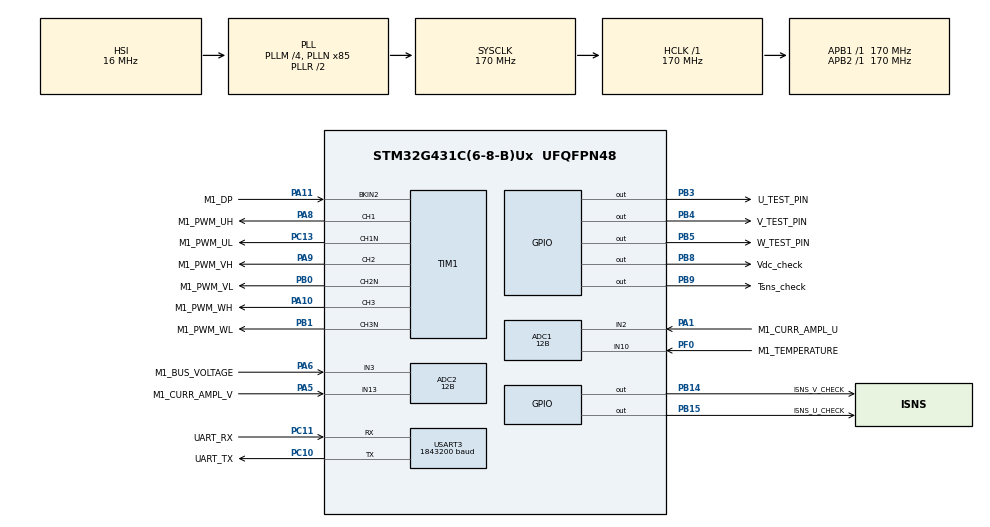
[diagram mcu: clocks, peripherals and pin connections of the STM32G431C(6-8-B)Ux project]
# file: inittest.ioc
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ADC1.Channel-1\#ChannelRegularConversion=ADC_CHANNEL_10
ADC1.ClockPrescaler=ADC_CLOCK_ASYNC_DIV1
ADC1.ContinuousConvMode=DISABLE
ADC1.DMAContinuousRequests=DISABLE
ADC1.DataAlign=ADC_DATAALIGN_LEFT
ADC1.DiscontinuousConvMode=DISABLE
ADC1.EOCSelection=ADC_EOC_SINGLE_CONV
ADC1.EnableAnalogWatchDog1=false
ADC1.EnableAnalogWatchDog2=false
ADC1.EnableAnalogWatchDog3=false
ADC1.EnableInjectedConversion=ENABLE
ADC1.EnableRegularConversion=ENABLE
ADC1.ExternalTrigConv=ADC_SOFTWARE_START
ADC1.ExternalTrigConvEdge=ADC_EXTERNALTRIGCONVEDGE_NONE
ADC1.ExternalTrigInjecConv=ADC_EXTERNALTRIGINJEC_T1_TRGO
ADC1.ExternalTrigInjecConvEdge=ADC_EXTERNALTRIGINJECCONV_EDGE_RISING
ADC1.InjNumberOfConversion=1
ADC1.InjectedChannel-1\#ChannelInjectedConversion=ADC_CHANNEL_2
ADC1.InjectedConvMode=None
ADC1.InjectedOffset-1\#ChannelInjectedConversion=0
ADC1.InjectedOffsetNumber-1\#ChannelInjectedConversion=ADC_OFFSET_NONE
ADC1.InjectedRank-1\#ChannelInjectedConversion=1
ADC1.InjectedSamplingTime-1\#ChannelInjectedConversion=ADC_SAMPLETIME_6CYCLES_5
ADC1.LowPowerAutoWait=DISABLE
ADC1.NbrOfConversion=1
ADC1.NbrOfConversionFlag=1
ADC1.Offset-1\#ChannelRegularConversion=0
ADC1.OffsetNumber-1\#ChannelRegularConversion=ADC_OFFSET_NONE
ADC1.Overrun=ADC_OVR_DATA_PRESERVED
ADC1.Rank-1\#ChannelRegularConversion=1
ADC1.Resolution=ADC_RESOLUTION_12B
ADC1.SamplingTime-1\#ChannelRegularConversion=ADC_SAMPLETIME_47CYCLES_5
ADC1.ScanConvMode=ADC_SCAN_DISABLE
ADC1.master=1
ADC2.Channel-1\#ChannelRegularConversion=ADC_CHANNEL_3
ADC2.ClockPrescaler=ADC_CLOCK_ASYNC_DIV1
ADC2.ContinuousConvMode=DISABLE
ADC2.DMAContinuousRequests=DISABLE
ADC2.DataAlign=ADC_DATAALIGN_LEFT
ADC2.DiscontinuousConvMode=DISABLE
ADC2.EOCSelection=ADC_EOC_SINGLE_CONV
ADC2.EnableAnalogWatchDog1=false
ADC2.EnableAnalogWatchDog2=false
ADC2.EnableAnalogWatchDog3=false
ADC2.EnableInjectedConversion=ENABLE
ADC2.EnableRegularConversion=ENABLE
ADC2.ExternalTrigConv=ADC_SOFTWARE_START
ADC2.ExternalTrigConvEdge=ADC_EXTERNALTRIGCONVEDGE_NONE
ADC2.ExternalTrigInjecConv=ADC_EXTERNALTRIGINJEC_T1_TRGO
ADC2.ExternalTrigInjecConvEdge=ADC_EXTERNALTRIGINJECCONV_EDGE_RISING
ADC2.InjNumberOfConversion=1
ADC2.InjectedChannel-1\#ChannelInjectedConversion=ADC_CHANNEL_13
ADC2.InjectedConvMode=None
ADC2.InjectedOffset-1\#ChannelInjectedConversion=0
ADC2.InjectedOffsetNumber-1\#ChannelInjectedConversion=ADC_OFFSET_NONE
ADC2.InjectedRank-1\#ChannelInjectedConversion=1
ADC2.InjectedSamplingTime-1\#ChannelInjectedConversion=ADC_SAMPLETIME_6CYCLES_5
ADC2.LowPowerAutoWait=DISABLE
ADC2.NbrOfConversion=1
ADC2.NbrOfConversionFlag=1
ADC2.Offset-1\#ChannelRegularConversion=0
ADC2.OffsetNumber-1\#ChannelRegularConversion=ADC_OFFSET_NONE
ADC2.Overrun=ADC_OVR_DATA_PRESERVED
ADC2.Rank-1\#ChannelRegularConversion=1
ADC2.Resolution=ADC_RESOLUTION_12B
ADC2.SamplingTime-1\#ChannelRegularConversion=ADC_SAMPLETIME_47CYCLES_5
ADC2.ScanConvMode=ADC_SCAN_DISABLE
ADC2.master=1
Dma.Request0=USART3_RX
Dma.Request1=USART3_TX
Dma.USART3_RX.0.Direction=DMA_PERIPH_TO_MEMORY
Dma.USART3_RX.0.EventEnable=DISABLE
Dma.USART3_RX.0.Instance=DMA1_Channel1
Dma.USART3_RX.0.MemDataAlignment=DMA_MDATAALIGN_BYTE
Dma.USART3_RX.0.MemInc=DMA_MINC_ENABLE
Dma.USART3_RX.0.Mode=DMA_NORMAL
Dma.USART3_RX.0.PeriphDataAlignment=DMA_PDATAALIGN_BYTE
Dma.USART3_RX.0.PeriphInc=DMA_PINC_DISABLE
Dma.USART3_RX.0.Polarity=HAL_DMAMUX_REQ_GEN_RISING
Dma.USART3_RX.0.Priority=DMA_PRIORITY_LOW
Dma.USART3_RX.0.RequestNumber=1
Dma.USART3_RX.0.SignalID=NONE
Dma.USART3_RX.0.SyncEnable=DISABLE
Dma.USART3_RX.0.SyncPolarity=HAL_DMAMUX_SYNC_NO_EVENT
Dma.USART3_RX.0.SyncRequestNumber=1
Dma.USART3_RX.0.SyncSignalID=NONE
Dma.USART3_TX.1.Direction=DMA_MEMORY_TO_PERIPH
Dma.USART3_TX.1.EventEnable=DISABLE
Dma.USART3_TX.1.Instance=DMA1_Channel2
Dma.USART3_TX.1.MemDataAlignment=DMA_MDATAALIGN_BYTE
Dma.USART3_TX.1.MemInc=DMA_MINC_ENABLE
Dma.USART3_TX.1.Mode=DMA_NORMAL
Dma.USART3_TX.1.PeriphDataAlignment=DMA_PDATAALIGN_BYTE
Dma.USART3_TX.1.PeriphInc=DMA_PINC_DISABLE
Dma.USART3_TX.1.Polarity=HAL_DMAMUX_REQ_GEN_RISING
Dma.USART3_TX.1.Priority=DMA_PRIORITY_LOW
Dma.USART3_TX.1.RequestNumber=1
Dma.USART3_TX.1.SignalID=NONE
Dma.USART3_TX.1.SyncEnable=DISABLE
Dma.USART3_TX.1.SyncPolarity=HAL_DMAMUX_SYNC_NO_EVENT
Dma.USART3_TX.1.SyncRequestNumber=1
Dma.USART3_TX.1.SyncSignalID=NONE
ExtraMW=MotorControl
ExtraMW.MotorControl.Config=MotorControl
ExtraMW.MotorControl.Mode=MotorControl
ExtraMW.MotorControl.Root=MCSDK_v6.4.1-Full/MotorControl
ExtraMW.MotorControl.Template=templates
Mcu.Family=STM32G4
Mcu.Name=STM32G431C(6-8-B)Ux
Mcu.Package=UFQFPN48
MotorControl.ADC_1_PERIPH=ADC1
MotorControl.ADC_2_PERIPH=ADC2
MotorControl.ADC_AHBPERIPH=RCC_AHBPeriph_ADC12
MotorControl.ADC_CLOCK_WB_DIV=1
MotorControl.ADC_PERIPH=ADC1
MotorControl.ADC_REFERENCE_VOLTAGE=3.3
MotorControl.BOARD=UAV
MotorControl.BUS_VOLTAGE_READING=true
MotorControl.CCMRAM_ENABLED=false
MotorControl.CLOCK_FREQUENCY=CPU_CLK_170_MHZ
MotorControl.CLOCK_SOURCE=INTERNAL
MotorControl.CPU_CLK_170_MHZ=true
MotorControl.CTLBOARD_NAME=UAV
MotorControl.CUBE_MX_VER=6.16.1
MotorControl.CURRENT_READING_TOPOLOGY=ICS_SENSORS
MotorControl.CURR_SAMPLING_TIME=6
MotorControl.DBG_MCU_LOAD_MEASURE=false
MotorControl.DEBUG_DAC_FUNCTIONALITY_EN=false
MotorControl.DP_EMERGENCY_STOP_GPIO_PIN=LL_GPIO_PIN_11
MotorControl.DP_EMERGENCY_STOP_GPIO_PORT=GPIOA
MotorControl.DRIVES_NUMBER_SELECTION=SINGLEDRIVE
MotorControl.DRIVE_NUMBER=1
MotorControl.DRIVE_TYPE=FOC
MotorControl.ENCODER_AVAILABLE=false
MotorControl.ENCODER_PPR=400
MotorControl.EXT_CLOCK_FREQUENCY=INT_RC_OSC
MotorControl.FEEDBACK_NET_FILTERING=false
MotorControl.FLASH_SIZE=128
MotorControl.HALL_SENSORS_AVAILABLE=false
MotorControl.HIGH_SIDE_IDLE_STATE=false
MotorControl.HWV_CS=TwoICSCurrents
MotorControl.HWV_DP=SingleErrorTrigger_FixedReference
MotorControl.HWV_PWM=DrivingHighAndLowSides
MotorControl.HW_COMPLEMENTED_LOW_SIDE=false
MotorControl.HW_DEAD_TIME_NS=100
MotorControl.ICS_SENSORS=true
MotorControl.INT_RC_OSC=true
MotorControl.IPs=CORDIC,SYS,NVIC,RCC,MotorControl,TIM1,ADC1,ADC2,USART3,DMA
MotorControl.LOW_MEMORY_FOOTPRINT_REG=false
MotorControl.LOW_SIDE_IDLE_STATE=false
MotorControl.LOW_SIDE_SIGNALS_ENABLING=LS_PWM_TIMER
MotorControl.M1_AMPLIFICATION_GAIN=0.044
MotorControl.M1_ANGC={0,0,0,0,0,0,0,0}
MotorControl.M1_AUXILIARY_SPEED_SENSOR=NONE
MotorControl.M1_BEMF_CONSISTENCY_GAIN=64
MotorControl.M1_BEMF_CONSISTENCY_TOL=64
MotorControl.M1_BOARD_MAX_CURRENT=13.4
MotorControl.M1_BUS_VOLTAGE_READING=true
MotorControl.M1_COMMUTATION_STEP_TIME_BUF_SIZE=12
MotorControl.M1_CONSTANT1_D=17939
MotorControl.M1_CONSTANT1_Q=17939
MotorControl.M1_CONSTANT2_QD=3341
MotorControl.M1_CS_ADC_NUM=2
MotorControl.M1_CS_ADC_PHASE_SHARED=NONE
MotorControl.M1_CS_ADC_U=ADC1
MotorControl.M1_CS_ADC_V=ADC2
MotorControl.M1_CS_CHANNEL_U=2
MotorControl.M1_CS_CHANNEL_V=13
MotorControl.M1_CURRENT_AMPLIFICATION_TOPO=EXTERNAL
MotorControl.M1_CURRENT_SENSING_TOPO=ICS_SENSORS
MotorControl.M1_CURR_SAMPLING_TIME=6
MotorControl.M1_DBG_OPEN_LOOP_ENABLE=true
MotorControl.M1_DC_CURRENT_RS_MEAS=13.4
MotorControl.M1_DEFAULT_CONTROL_MODE=STC_SPEED_MODE
MotorControl.M1_DEFAULT_FLUX_COMPONENT=0
MotorControl.M1_DEFAULT_TARGET_SPEED_RPM=4320
MotorControl.M1_DEFAULT_TORQUE_COMPONENT=0
MotorControl.M1_DISCONTINUOUS_PWM=false
MotorControl.M1_DP_BKIN_FILTER=1
MotorControl.M1_DP_BKIN_MODE=EXT_MODE
MotorControl.M1_DP_BKIN_POLARITY=EMSTOP_ACTIVE_LOW
MotorControl.M1_DP_DESTINATION=TIM_BKIN2
MotorControl.M1_DP_TOPOLOGY=EXTERNAL
MotorControl.M1_DRIVE_TYPE=FOC
MotorControl.M1_ENABLE_SL_ALGO_FROM_PHASE=2
MotorControl.M1_ENCODER_PPR=400
MotorControl.M1_F1=8192
MotorControl.M1_F2=16384
MotorControl.M1_FEED_FORWARD_CURRENT_REG_ENABLING=false
MotorControl.M1_FLUX_WEAKENING_ENABLING=false
MotorControl.M1_FW_KIDIV=32768
MotorControl.M1_FW_KI_GAIN=5000
MotorControl.M1_FW_KPDIV=32768
MotorControl.M1_FW_KP_GAIN=3000
MotorControl.M1_FW_VOLTAGE_REF=985
MotorControl.M1_GAIN1=-11648
MotorControl.M1_GAIN2=8582
MotorControl.M1_HALL_PHASE_SHIFT=300
MotorControl.M1_HALL_SENSORS_PLACEMENT=DEGREES_120
MotorControl.M1_HIGH_SIDE_IDLE_STATE=false
MotorControl.M1_HW_DEAD_TIME_NS=100
MotorControl.M1_ICL_ENABLED=false
MotorControl.M1_ID_DEMAG=-13.4
MotorControl.M1_IQMAX=13.4
MotorControl.M1_LDLQ_RATIO=1.000
MotorControl.M1_LOW_SIDE_IDLE_STATE=false
MotorControl.M1_LOW_SIDE_SIGNALS_ENABLING=LS_PWM_TIMER
MotorControl.M1_LS=0.00003
MotorControl.M1_MAX_APPLICATION_SPEED=12000
MotorControl.M1_MAX_MODULATION_INDEX=100
MotorControl.M1_MIN_APPLICATION_SPEED=0
MotorControl.M1_MOTOR_MAX_SPEED_RPM=12000
MotorControl.M1_MOTOR_NAME=ECX 42 flat UAV
MotorControl.M1_MOTOR_RATED_FLUX=0.010532806
MotorControl.M1_MOTOR_VOLTAGE_CONSTANT=1.7
MotorControl.M1_MTPA_ENABLING=false
MotorControl.M1_NB_CONSECUTIVE_TESTS=2
MotorControl.M1_NOMINAL_BUS_VOLTAGE_V=48
MotorControl.M1_NOMINAL_CURRENT=13.4
MotorControl.M1_OBS_MINIMUM_SPEED_RPM=1500
MotorControl.M1_OCP_TOPOLOGY=NONE
MotorControl.M1_OFST={0,0,0,0,0,0,0,0}
MotorControl.M1_ON_OVER_VOLTAGE=TURN_OFF_PWM
MotorControl.M1_OVERMODULATION=false
MotorControl.M1_OVP_THRESHOLD_HIGH=50
MotorControl.M1_OV_TEMPERATURE_HYSTERESIS_C=10
MotorControl.M1_OV_TEMPERATURE_PROT_ENABLING=true
MotorControl.M1_OV_TEMPERATURE_THRESHOLD_C=120
MotorControl.M1_OV_VOLTAGE_PROT_ENABLING=true
MotorControl.M1_OV_VOLTAGE_THRESHOLD_V=50
MotorControl.M1_PHASE1_DURATION=300
MotorControl.M1_PHASE1_FINAL_CURRENT=3
MotorControl.M1_PHASE1_FINAL_SPEED_RPM=0
MotorControl.M1_PHASE2_DURATION=1200
MotorControl.M1_PHASE2_FINAL_CURRENT=4
MotorControl.M1_PHASE2_FINAL_SPEED_RPM=2500
MotorControl.M1_PHASE3_DURATION=0
MotorControl.M1_PHASE3_FINAL_CURRENT=13.4
MotorControl.M1_PHASE3_FINAL_SPEED_RPM=4800
MotorControl.M1_PHASE4_DURATION=0
MotorControl.M1_PHASE4_FINAL_CURRENT=13.4
MotorControl.M1_PHASE4_FINAL_SPEED_RPM=4800
MotorControl.M1_PHASE5_DURATION=0
MotorControl.M1_PHASE5_FINAL_CURRENT=13.4
MotorControl.M1_PHASE5_FINAL_SPEED_RPM=4800
MotorControl.M1_PID_FLUX_KD_DEFAULT=100
MotorControl.M1_PID_FLUX_KI_DEFAULT=480
MotorControl.M1_PID_FLUX_KP_DEFAULT=2304
MotorControl.M1_PID_SPEED_KD_DEFAULT=0
MotorControl.M1_PID_SPEED_KI_DEFAULT=23
MotorControl.M1_PID_SPEED_KP_DEFAULT=3287
MotorControl.M1_PID_TORQUE_KD_DEFAULT=100
MotorControl.M1_PID_TORQUE_KI_DEFAULT=480
MotorControl.M1_PID_TORQUE_KP_DEFAULT=2304
MotorControl.M1_PLL_KI_GAIN=141
MotorControl.M1_PLL_KP_GAIN=3192
MotorControl.M1_POLE_PAIR_NUM=8
MotorControl.M1_POSITION_CTRL_ENABLING=false
MotorControl.M1_POTENTIOMETER_ENABLE=false
MotorControl.M1_POWERBOARD_NAME=UAV
MotorControl.M1_PWM_CHARGE_BOOT_CAP_DUTY_CYCLES=0.000
MotorControl.M1_PWM_CHARGE_BOOT_CAP_MS=10
MotorControl.M1_PWM_DRIVER_PN=ISG3201
MotorControl.M1_PWM_FREQUENCY=16000
MotorControl.M1_PWM_TIMER_BRK_IRQ=TIM1_BRK_TIM15
MotorControl.M1_PWM_TIMER_SELECTION=PWM_TIM1
MotorControl.M1_PWM_TIMER_UP_IRQ=TIM1_UP_TIM16
MotorControl.M1_REGULATION_EXECUTION_RATE=1
MotorControl.M1_RS=0.05
MotorControl.M1_SEGDIV=0
MotorControl.M1_SHARED_SIGNAL_ENABLE=false
MotorControl.M1_SPD_DIFFERENTIAL_TERM_ENABLING=false
MotorControl.M1_SPEED_BAND_LOWER_LIMIT=15
MotorControl.M1_SPEED_BAND_UPPER_LIMIT=17
MotorControl.M1_SPEED_FEEDBACK_CHECK=true
MotorControl.M1_SPEED_LOOP_FREQUENCY_HZ=1000
MotorControl.M1_SPEED_SENSOR=STO_PLL
MotorControl.M1_SP_KDDIV=16
MotorControl.M1_SP_KIDIV=16384
MotorControl.M1_SP_KPDIV=2048
MotorControl.M1_SS_MEAS_ERRORS_BEFORE_FAULTS=255
MotorControl.M1_STARTING_ANGLE_DEG=0
MotorControl.M1_STO_FIFO_DEPTH_01HZ=64
MotorControl.M1_STO_FIFO_DEPTH_DPP=64
MotorControl.M1_SW_DEADTIME_NS=75
MotorControl.M1_T0_C=25
MotorControl.M1_TEMPERATURE_READING=true
MotorControl.M1_TEMP_ADC_SAMPLING_TIME=47
MotorControl.M1_TEMP_FDBK_ADC=ADC1
MotorControl.M1_TEMP_FDBK_CHANNEL=ADC_CHANNEL_10
MotorControl.M1_TF_KDDIV=8192
MotorControl.M1_TF_KIDIV=16384
MotorControl.M1_TF_KPDIV=8192
MotorControl.M1_TNOISE_NS=200
MotorControl.M1_TRANSITION_DURATION=25
MotorControl.M1_TRISE_NS=200
MotorControl.M1_T_MAX=120
MotorControl.M1_UD_VOLTAGE_THRESHOLD_V=4
MotorControl.M1_USE_INTERNAL_OPAMP=false
MotorControl.M1_UV_VOLTAGE_PROT_ENABLING=true
MotorControl.M1_V0_V=1.1
MotorControl.M1_VARIANCE_THRESHOLD=1
MotorControl.M1_VBUS_ADC=ADC2
MotorControl.M1_VBUS_ADC_SAMPLING_TIME=47
MotorControl.M1_VBUS_CHANNEL=ADC_CHANNEL_3
MotorControl.M1_VBUS_PARTITIONING_FACTOR=0.03194888178913738
MotorControl.M1_dV_dT=0.033
MotorControl.MAX_READABLE_CURRENT=37.5
MotorControl.MCPA_OVER_UART_A_STREAM=10
MotorControl.MCP_ASPEP_OVER_UART=true
MotorControl.MCP_ASYNC_EN=true
MotorControl.MCP_ASYNC_OVER_ASPEP_EN=true
MotorControl.MCP_ASYNC_OVER_UART_A_EN=true
MotorControl.MCP_DMACH_RX_UART_A=1
MotorControl.MCP_DMACH_TX_UART_A=2
MotorControl.MCP_DMA_RX_UART_A=DMA1
MotorControl.MCP_DMA_TX_UART_A=DMA1
MotorControl.MCP_EN=true
MotorControl.MCP_IRQ_HANDLER_DMA_RX_UART_A=DMA1_Channel1_IRQHandler
MotorControl.MCP_IRQ_HANDLER_UART_A=USART3_IRQHandler
MotorControl.MCP_OVER_ASPEP_EN=true
MotorControl.MCP_OVER_STLNK_EN=false
MotorControl.MCP_OVER_UART_A_EN=true
MotorControl.MCP_OVER_UART_B_EN=false
MotorControl.MCP_RX_SYNC_PAYLOAD_MAX=256
MotorControl.MCP_TX_ASYNC_PAYLOAD_MAX_UART_A=2048
MotorControl.MCP_TX_SYNC_PAYLOAD_MAX=256
MotorControl.MCU=STM32G431CB
MotorControl.MCU_FAMILY=STM32G4
MotorControl.MCU_LINE=STM32G4x1
MotorControl.MCU_NAME=STM32G431C(6-8-B)Ux
MotorControl.MCU_PACKAGE=UFQFPN48
MotorControl.MCU_TYPE=STM32G431CB
MotorControl.MCU_USERNAME=STM32G431CBUx
MotorControl.MC_WORKBENCH_VERSION=6.4.1
MotorControl.MOTOR_PROFILER=false
MotorControl.MOTOR_TYPE=PMSM
MotorControl.ON_OVER_VOLTAGE=TURN_OFF_PWM
MotorControl.OV_TEMPERATURE_PROT_ENABLING=true
MotorControl.OV_VOLTAGE_PROT_ENABLING=true
MotorControl.PHASE_UH_GPIO_PIN=LL_GPIO_PIN_8
MotorControl.PHASE_UH_GPIO_PORT=GPIOA
MotorControl.PHASE_UH_POLARITY=H_ACTIVE_HIGH
MotorControl.PHASE_UL_GPIO_PIN=LL_GPIO_PIN_13
MotorControl.PHASE_UL_GPIO_PORT=GPIOC
MotorControl.PHASE_UL_POLARITY=L_ACTIVE_HIGH
MotorControl.PHASE_U_CURR_ADC=ADC1
MotorControl.PHASE_U_CURR_CHANNEL=ADC_CHANNEL_2
MotorControl.PHASE_U_GPIO_PIN=LL_GPIO_PIN_1
MotorControl.PHASE_U_GPIO_PORT=GPIOA
MotorControl.PHASE_U_PWM_CHANNEL=TIM_Channel_1
MotorControl.PHASE_VH_GPIO_PIN=LL_GPIO_PIN_9
MotorControl.PHASE_VH_GPIO_PORT=GPIOA
MotorControl.PHASE_VH_POLARITY=H_ACTIVE_HIGH
MotorControl.PHASE_VL_GPIO_PIN=LL_GPIO_PIN_0
MotorControl.PHASE_VL_GPIO_PORT=GPIOB
MotorControl.PHASE_VL_POLARITY=L_ACTIVE_HIGH
MotorControl.PHASE_V_CURR_ADC=ADC2
MotorControl.PHASE_V_CURR_CHANNEL=ADC_CHANNEL_13
MotorControl.PHASE_V_GPIO_PIN=LL_GPIO_PIN_5
MotorControl.PHASE_V_GPIO_PORT=GPIOA
MotorControl.PHASE_V_PWM_CHANNEL=TIM_Channel_2
MotorControl.PHASE_WH_GPIO_PIN=LL_GPIO_PIN_10
MotorControl.PHASE_WH_GPIO_PORT=GPIOA
MotorControl.PHASE_WH_POLARITY=H_ACTIVE_HIGH
MotorControl.PHASE_WL_GPIO_PIN=LL_GPIO_PIN_1
MotorControl.PHASE_WL_GPIO_PORT=GPIOB
MotorControl.PHASE_WL_POLARITY=L_ACTIVE_HIGH
MotorControl.PHASE_W_PWM_CHANNEL=TIM_Channel_3
MotorControl.POTENTIOMETER_READING=false
MotorControl.PWM_FREQUENCY=16000
MotorControl.PWM_TIMER_SELECTION=PWM_TIM1
MotorControl.REGULATION_EXECUTION_RATE=1
MotorControl.RTOS=NONE
MotorControl.R_BRAKE_SWITCH_OFF_THRES_V=40
MotorControl.SINGLEDRIVE=true
MotorControl.SPD_DIFFERENTIAL_TERM_ENABLING=false
MotorControl.SPEED_SENSOR_SELECTION=STATE_OBSERVER_PLL
MotorControl.START_STOP_BTN=false
MotorControl.STATE_OBSERVER_PLL=true
MotorControl.STM32G431CB=true
MotorControl.SW_DEADTIME_NS=75
MotorControl.TEMPERATURE_READING=true
MotorControl.TEMP_ADC_SAMPLING_TIME=47
MotorControl.TEMP_FDBK_ADC=ADC1
MotorControl.TEMP_FDBK_CHANNEL=ADC_CHANNEL_10
MotorControl.TEMP_FDBK_GPIO_PIN=LL_GPIO_PIN_0
MotorControl.TEMP_FDBK_GPIO_PORT=GPIOF
MotorControl.TFDIFFERENTIAL_TERM_ENABLING=false
MotorControl.TRISE_NS=200
MotorControl.USART_RX_GPIO_PIN=LL_GPIO_PIN_11
MotorControl.USART_RX_GPIO_PORT=GPIOC
MotorControl.USART_SELECTION=USE_USART3
MotorControl.USART_SELECTION_A=USART3
MotorControl.USART_SPEED=1843200
MotorControl.USART_TX_GPIO_PIN=LL_GPIO_PIN_10
MotorControl.USART_TX_GPIO_PORT=GPIOC
MotorControl.USE_3OPAMPS=false
MotorControl.USE_INTERNAL_OPAMP=false
MotorControl.UV_VOLTAGE_PROT_ENABLING=true
MotorControl.VBUS_ADC=ADC2
MotorControl.VBUS_ADC_SAMPLING_TIME=47
MotorControl.VBUS_CHANNEL=ADC_CHANNEL_3
MotorControl.VBUS_GPIO_PIN=LL_GPIO_PIN_6
MotorControl.VBUS_GPIO_PORT=GPIOA
MotorControl.WB_MX_HEAPSIZE=0x200
MotorControl.WB_MX_STACKSIZE=0x400
MotorControl.WB_MX_TRUSTZONE_AVAILABLE=false
MotorControl.WB_UI_CUTOFF_FREQUENCY=6000
MotorControl.WB_UI_DP_DISABLING_ENABLE=false
MotorControl.WB_UI_ENCODER_HAS_INDEX_PIN=false
MotorControl.WB_UI_FLUX_TARGET=0
MotorControl.WB_UI_FRICTION=0.49
MotorControl.WB_UI_INERTIA=0.55
MotorControl.WB_UI_MAGNETIC_STRUCTURE=SM-PMSM
MotorControl.WB_UI_MAX_CURRENT=13.4
MotorControl.WB_UI_MAX_NOMINAL_DC_VOLTAGE=48
MotorControl.WB_UI_MAX_PWMFREQUENCY=100000
MotorControl.WB_UI_MOTOR_DESCRIPTION=ECX 42 flat UAV motor test
MotorControl.WB_UI_PW_BOARD_MAX_RATED_CURRENT=30
MotorControl.WB_UI_PW_BOARD_MAX_VOLTAGE=50
MotorControl.WB_UI_PW_BOARD_MIN_VOLTAGE=4
MotorControl.WB_to_Mx_template_version=25-05-06
MotorControl.WB_to_Mx_version=6.4.1-RC1-Full
NVIC.ADC1_2_IRQn=true\:2\:0\:true\:true\:false\:5\:true\:true\:true
NVIC.DMA1_Channel1_IRQn=true\:3\:0\:true\:true\:false\:2\:true\:true\:true
NVIC.PriorityGroup=NVIC_PRIORITYGROUP_3
NVIC.TIM1_BRK_TIM15_IRQn=true\:4\:1\:true\:true\:false\:3\:true\:true\:true
NVIC.TIM1_UP_TIM16_IRQn=true\:0\:0\:false\:true\:false\:4\:true\:true\:true
NVIC.USART3_IRQn=true\:3\:1\:true\:true\:false\:1\:true\:true\:true
PA1.GPIO_Label=M1_CURR_AMPL_U
PA1.Mode=IN2-Single-Ended
PA1.Signal=ADC1_IN2
PA10.GPIO_Label=M1_PWM_WH
PA10.GPIO_PuPd=GPIO_PULLDOWN
PA10.GPIO_Speed=GPIO_SPEED_FREQ_HIGH
PA10.Signal=S_TIM1_CH3
PA11.GPIO_Label=M1_DP
PA11.GPIO_PuPd=GPIO_PULLUP
PA11.Mode=Activate-Break-Input-2
PA11.Signal=TIM1_BKIN2
PA13.GPIO_Label=TMS
PA13.Mode=Serial_Wire
PA13.Signal=SYS_JTMS-SWDIO
PA14.GPIO_Label=TCK
PA14.Mode=Serial_Wire
PA14.Signal=SYS_JTCK-SWCLK
PA5.GPIO_Label=M1_CURR_AMPL_V
PA5.Mode=IN13-Single-Ended
PA5.Signal=ADC2_IN13
PA6.GPIO_Label=M1_BUS_VOLTAGE
PA6.Mode=IN3-Single-Ended
PA6.Signal=ADC2_IN3
PA8.GPIO_Label=M1_PWM_UH
PA8.GPIO_PuPd=GPIO_PULLDOWN
PA8.GPIO_Speed=GPIO_SPEED_FREQ_HIGH
PA8.Signal=S_TIM1_CH1
PA9.GPIO_Label=M1_PWM_VH
PA9.GPIO_PuPd=GPIO_PULLDOWN
PA9.GPIO_Speed=GPIO_SPEED_FREQ_HIGH
PA9.Signal=S_TIM1_CH2
PB0.GPIO_Label=M1_PWM_VL
PB0.GPIO_PuPd=GPIO_PULLDOWN
PB0.GPIO_Speed=GPIO_SPEED_FREQ_HIGH
PB0.Mode=PWM Generation2 CH2 CH2N
PB0.Signal=TIM1_CH2N
PB1.GPIO_Label=M1_PWM_WL
PB1.GPIO_PuPd=GPIO_PULLDOWN
PB1.GPIO_Speed=GPIO_SPEED_FREQ_HIGH
PB1.Mode=PWM Generation3 CH3 CH3N
PB1.Signal=TIM1_CH3N
PB14.GPIO_Label=ISNS_V_CHECK
PB14.Signal=GPIO_Output
PB15.GPIO_Label=ISNS_U_CHECK
PB15.Signal=GPIO_Output
PB3.GPIO_Label=U_TEST_PIN
PB3.Signal=GPIO_Output
PB4.GPIO_Label=V_TEST_PIN
PB4.Signal=GPIO_Output
PB5.GPIO_Label=W_TEST_PIN
PB5.Signal=GPIO_Output
PB8-BOOT0.GPIO_Label=Vdc_check
PB8-BOOT0.Signal=GPIO_Output
PB9.GPIO_Label=Tsns_check
PB9.Signal=GPIO_Output
PC10.GPIO_Label=UART_TX
PC10.GPIO_Mode=GPIO_MODE_AF_PP
PC10.GPIO_PuPd=GPIO_NOPULL
PC10.GPIO_Speed=GPIO_SPEED_FREQ_LOW
PC10.Mode=Asynchronous
PC10.Signal=USART3_TX
PC11.GPIO_Label=UART_RX
PC11.GPIO_Mode=GPIO_MODE_AF_PP
PC11.GPIO_PuPd=GPIO_NOPULL
PC11.GPIO_Speed=GPIO_SPEED_FREQ_LOW
PC11.Mode=Asynchronous
PC11.Signal=USART3_RX
PC13.GPIO_Label=M1_PWM_UL
PC13.GPIO_PuPd=GPIO_PULLDOWN
PC13.GPIO_Speed=GPIO_SPEED_FREQ_HIGH
PC13.Mode=PWM Generation1 CH1 CH1N
PC13.Signal=TIM1_CH1N
PF0-OSC_IN.GPIO_Label=M1_TEMPERATURE
PF0-OSC_IN.Mode=IN10-Single-Ended
PF0-OSC_IN.Signal=ADC1_IN10
ProjectManager.HeapSize=0x200
ProjectManager.StackSize=0x400
ProjectManager.TargetToolchain=STM32CubeIDE
RCC.ADC12CLockSelection=RCC_ADC12CLKSOURCE_PLL
RCC.ADC12Freq_Value=42500000
RCC.AHBFreq_Value=170000000
RCC.APB1Freq_Value=170000000
RCC.APB1TimFreq_Value=170000000
RCC.APB2Freq_Value=170000000
RCC.APB2TimFreq_Value=170000000
RCC.CK48CLockSelection=RCC_USBCLKSOURCE_PLL
RCC.CortexFreq_Value=170000000
RCC.EXTERNAL_CLOCK_VALUE=12288000
RCC.HCLKFreq_Value=170000000
RCC.HSE_VALUE=8000000
RCC.HSI48_VALUE=48000000
RCC.HSI_VALUE=16000000
RCC.LSE_VALUE=32768
RCC.PLLM=RCC_PLLM_DIV4
RCC.PLLN=85
RCC.PLLP=RCC_PLLP_DIV8
RCC.PREFETCH_ENABLE=1
RCC.SYSCLKFreq_VALUE=170000000
RCC.SYSCLKSource=RCC_SYSCLKSOURCE_PLLCLK
RCC.USBFreq_Value=170000000
RCC.VCOOutputFreq_Value=340000000
SH.S_TIM1_CH1.0=TIM1_CH1,PWM Generation1 CH1 CH1N
SH.S_TIM1_CH2.0=TIM1_CH2,PWM Generation2 CH2 CH2N
SH.S_TIM1_CH3.0=TIM1_CH3,PWM Generation3 CH3 CH3N
TIM1.AutoReloadPreload=TIM_AUTORELOAD_PRELOAD_DISABLE
TIM1.AutomaticOutput=TIM_AUTOMATICOUTPUT_DISABLE
TIM1.Break2Filter=1
TIM1.Break2Polarity=TIM_BREAK2POLARITY_HIGH
TIM1.Break2State=TIM_BREAK2_ENABLE
TIM1.BreakFilter=0
TIM1.BreakPolarity=TIM_BREAKPOLARITY_HIGH
TIM1.BreakState=TIM_BREAK_DISABLE
TIM1.Channel=TIM_CHANNEL_4
TIM1.Channel-PWM\ Generation1\ CH1\ CH1N=TIM_CHANNEL_1
TIM1.Channel-PWM\ Generation2\ CH2\ CH2N=TIM_CHANNEL_2
TIM1.Channel-PWM\ Generation3\ CH3\ CH3N=TIM_CHANNEL_3
TIM1.Channel-PWM\ Generation4\ No\ Output=TIM_CHANNEL_4
TIM1.ClearInputSource=TIM_CLEARINPUTSOURCE_NONE
TIM1.ClockDivision=TIM_CLOCKDIVISION_DIV2
TIM1.CounterMode=TIM_COUNTERMODE_CENTERALIGNED1
TIM1.DeadTime=((DEAD_TIME_COUNTS) / 2)
TIM1.LockLevel=TIM_LOCKLEVEL_OFF
TIM1.OC1Preload_PWM=ENABLE
TIM1.OC2Preload_PWM=ENABLE
TIM1.OC3Preload_PWM=ENABLE
TIM1.OC4Preload_PWM=ENABLE
TIM1.OCFastMode_PWM=TIM_OCFAST_DISABLE
TIM1.OCIdleState_1=TIM_OCIDLESTATE_RESET
TIM1.OCIdleState_2=TIM_OCIDLESTATE_RESET
TIM1.OCIdleState_3=TIM_OCIDLESTATE_RESET
TIM1.OCIdleState_4=TIM_OCIDLESTATE_RESET
TIM1.OCMode_PWM-PWM\ Generation1\ CH1\ CH1N=TIM_OCMODE_PWM1
TIM1.OCMode_PWM-PWM\ Generation2\ CH2\ CH2N=TIM_OCMODE_PWM1
TIM1.OCMode_PWM-PWM\ Generation3\ CH3\ CH3N=TIM_OCMODE_PWM1
TIM1.OCMode_PWM-PWM\ Generation4\ No\ Output=TIM_OCMODE_PWM2
TIM1.OCNIdleState_1=TIM_OCNIDLESTATE_RESET
TIM1.OCNIdleState_2=TIM_OCNIDLESTATE_RESET
TIM1.OCNIdleState_3=TIM_OCNIDLESTATE_RESET
TIM1.OCNPolarity_1=TIM_OCNPOLARITY_HIGH
TIM1.OCNPolarity_2=TIM_OCNPOLARITY_HIGH
TIM1.OCNPolarity_3=TIM_OCNPOLARITY_HIGH
TIM1.OCPolarity_1=TIM_OCPOLARITY_HIGH
TIM1.OCPolarity_2=TIM_OCPOLARITY_HIGH
TIM1.OCPolarity_3=TIM_OCPOLARITY_HIGH
TIM1.OCPolarity_4=TIM_OCPOLARITY_HIGH
TIM1.OffStateIDLEMode=TIM_OSSI_ENABLE
TIM1.OffStateRunMode=TIM_OSSR_ENABLE
TIM1.PeriodNoDither=((PWM_PERIOD_CYCLES) / 2)
TIM1.Prescaler=((TIM_CLOCK_DIVIDER) - 1)
TIM1.PulseNoDither_1=((PWM_PERIOD_CYCLES) / 4)
TIM1.PulseNoDither_2=((PWM_PERIOD_CYCLES) / 4)
TIM1.PulseNoDither_3=((PWM_PERIOD_CYCLES) / 4)
TIM1.PulseNoDither_4=(((PWM_PERIOD_CYCLES) / 2) - (HTMIN))
TIM1.RepetitionCounter=(REP_COUNTER)
TIM1.SourceBRK2DigInput=TIM_BREAKINPUTSOURCE_ENABLE
TIM1.SourceBRK2DigInputPolarity=TIM_BREAKINPUTSOURCE_POLARITY_LOW
TIM1.SourceBRKDigInput=TIM_BREAKINPUTSOURCE_DISABLE
TIM1.TIM_MasterOutputTrigger=TIM_TRGO_OC4REF
TIM1.TIM_MasterOutputTrigger2=TIM_TRGO2_RESET
TIM1.TIM_MasterSlaveMode=TIM_MASTERSLAVEMODE_DISABLE
TIM1.TIM_SlaveMode=TIM_SLAVEMODE_TRIGGER
USART3.BaudRate=1843200
USART3.VirtualMode-Asynchronous=VM_ASYNC
USART3.WordLength=WORDLENGTH_8B
VP_CORDIC_VS_CORDIC.Mode=CORDIC_Activate
VP_MotorControl_MC_ENABLED.Mode=Enabled
VP_SYS_VS_DBSignals.Mode=DisableDeadBatterySignals
VP_TIM1_VS_no_output4.Mode=PWM Generation4 No Output
board=custom

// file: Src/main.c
/* USER CODE BEGIN Header */
/**
  ******************************************************************************
  * @file           : main.c
  * @brief          : Main program body
  ******************************************************************************
  * @attention
  *
  * Copyright (c) 2026 STMicroelectronics.
  * All rights reserved.
  *
  * This software is licensed under terms that can be found in the LICENSE file
  * in the root directory of this software component.
  * If no LICENSE file comes with this software, it is provided AS-IS.
  *
  ******************************************************************************
  */
/* USER CODE END Header */
#include "main.h"

/* USER CODE BEGIN Includes */
#include <stdbool.h>
#include <string.h>
#include <stdio.h>
#include "mc_api.h"
#include "mc_config.h"
#include "r_divider_bus_voltage_sensor.h"
#include "ntc_temperature_sensor.h"
#include "ics_g4xx_pwm_curr_fdbk.h"
/* USER CODE END Includes */

ADC_HandleTypeDef hadc1;
ADC_HandleTypeDef hadc2;

CORDIC_HandleTypeDef hcordic;

TIM_HandleTypeDef htim1;

UART_HandleTypeDef huart3;
DMA_HandleTypeDef hdma_usart3_rx;
DMA_HandleTypeDef hdma_usart3_tx;

/* USER CODE BEGIN PV */
/* 觀測時間窗：16kHz 的 PWM 用 20~50ms 都很夠；我給 50ms 保守 */
#define UVW_SELFTEST_WINDOW_MS  (20u)

/* PASS 後 toggle 週期 */
#define UVW_TOGGLE_MS           (100u)

/* 用 GPIOB 的 PB3/PB4/PB5 當 test pin */
#define U_TEST_PORT  GPIOB
#define U_TEST_PIN   GPIO_PIN_3   // PB3
#define V_TEST_PORT  GPIOB
#define V_TEST_PIN   GPIO_PIN_4   // PB4
#define W_TEST_PORT  GPIOB
#define W_TEST_PIN   GPIO_PIN_5   // PB5
// for Isns check
#define ISNS_U_CHECK_PORT        GPIOB
#define ISNS_U_CHECK_PIN         GPIO_PIN_15   // IsnsU -> PB15

#define ISNS_V_CHECK_PORT      GPIOB
#define ISNS_V_CHECK_PIN       GPIO_PIN_14   // IsnsV -> PB14

#define ISNS_CHECK_TOGGLE_MS   100u

// bidirectional + 3.3V，0A 時理論中心點約 1.65V
#define ISNS_VOLTAGE_MIN       1.45f
#define ISNS_VOLTAGE_MAX       1.85f

/* Calibration Constants for VBUS derived from empirical data */
#define VBUS_CALIB_GAIN   0.986969f
#define VBUS_CALIB_OFFSET 0.520000f
/* Threshold to mask out USB backfeeding noise (e.g., voltages under 3.5V are treated as 0V) */
#define VBUS_NOISE_DEADBAND_V 3.5f

#define NTC_TABLE_SIZE 331U
/* USER CODE END PV */

void SystemClock_Config(void);
static void MX_GPIO_Init(void);
static void MX_DMA_Init(void);
static void MX_ADC1_Init(void);
static void MX_ADC2_Init(void);
static void MX_CORDIC_Init(void);
static void MX_TIM1_Init(void);
static void MX_USART3_UART_Init(void);
static void MX_NVIC_Init(void);

/* USER CODE BEGIN 0 */

//for Tsns
typedef struct
{
    float temp_c;
    uint16_t adc;
} ntc_lut_t;

const ntc_lut_t NTC_LUT[NTC_TABLE_SIZE] = {
    { -40.0f,   848 },
    { -39.5f,   880 },
    { -39.0f,   912 },
    { -38.5f,   944 },
    { -38.0f,   976 },
    { -37.5f,  1008 },
    { -37.0f,  1040 },
    { -36.5f,  1072 },
    { -36.0f,  1120 },
    { -35.5f,  1152 },
    { -35.0f,  1184 },
    { -34.5f,  1232 },
    { -34.0f,  1280 },
    { -33.5f,  1312 },
    { -33.0f,  1360 },
    { -32.5f,  1408 },
    { -32.0f,  1456 },
    { -31.5f,  1504 },
    { -31.0f,  1552 },
    { -30.5f,  1600 },
    { -30.0f,  1664 },
    { -29.5f,  1712 },
    { -29.0f,  1760 },
    { -28.5f,  1824 },
    { -28.0f,  1888 },
    { -27.5f,  1936 },
    { -27.0f,  2000 },
    { -26.5f,  2064 },
    { -26.0f,  2128 },
    { -25.5f,  2192 },
    { -25.0f,  2272 },
    { -24.5f,  2336 },
    { -24.0f,  2416 },
    { -23.5f,  2480 },
    { -23.0f,  2560 },
    { -22.5f,  2640 },
    { -22.0f,  2720 },
    { -21.5f,  2800 },
    { -21.0f,  2880 },
    { -20.5f,  2960 },
    { -20.0f,  3056 },
    { -19.5f,  3136 },
    { -19.0f,  3232 },
    { -18.5f,  3328 },
    { -18.0f,  3424 },
    { -17.5f,  3520 },
    { -17.0f,  3616 },
    { -16.5f,  3728 },
    { -16.0f,  3824 },
    { -15.5f,  3936 },
    { -15.0f,  4048 },
    { -14.5f,  4160 },
    { -14.0f,  4272 },
    { -13.5f,  4400 },
    { -13.0f,  4512 },
    { -12.5f,  4640 },
    { -12.0f,  4768 },
    { -11.5f,  4896 },
    { -11.0f,  5024 },
    { -10.5f,  5152 },
    { -10.0f,  5280 },
    {  -9.5f,  5424 },
    {  -9.0f,  5568 },
    {  -8.5f,  5712 },
    {  -8.0f,  5856 },
    {  -7.5f,  6000 },
    {  -7.0f,  6160 },
    {  -6.5f,  6320 },
    {  -6.0f,  6464 },
    {  -5.5f,  6624 },
    {  -5.0f,  6800 },
    {  -4.5f,  6960 },
    {  -4.0f,  7136 },
    {  -3.5f,  7312 },
    {  -3.0f,  7472 },
    {  -2.5f,  7664 },
    {  -2.0f,  7840 },
    {  -1.5f,  8032 },
    {  -1.0f,  8208 },
    {  -0.5f,  8400 },
    {   0.0f,  8592 },
    {   0.5f,  8800 },
    {   1.0f,  8992 },
    {   1.5f,  9200 },
    {   2.0f,  9408 },
    {   2.5f,  9616 },
    {   3.0f,  9824 },
    {   3.5f, 10032 },
    {   4.0f, 10256 },
    {   4.5f, 10480 },
    {   5.0f, 10704 },
    {   5.5f, 10928 },
    {   6.0f, 11152 },
    {   6.5f, 11392 },
    {   7.0f, 11632 },
    {   7.5f, 11872 },
    {   8.0f, 12112 },
    {   8.5f, 12352 },
    {   9.0f, 12608 },
    {   9.5f, 12848 },
    {  10.0f, 13104 },
    {  10.5f, 13360 },
    {  11.0f, 13616 },
    {  11.5f, 13888 },
    {  12.0f, 14144 },
    {  12.5f, 14416 },
    {  13.0f, 14688 },
    {  13.5f, 14960 },
    {  14.0f, 15232 },
    {  14.5f, 15504 },
    {  15.0f, 15792 },
    {  15.5f, 16080 },
    {  16.0f, 16352 },
    {  16.5f, 16640 },
    {  17.0f, 16944 },
    {  17.5f, 17232 },
    {  18.0f, 17520 },
    {  18.5f, 17824 },
    {  19.0f, 18112 },
    {  19.5f, 18416 },
    {  20.0f, 18720 },
    {  20.5f, 19024 },
    {  21.0f, 19328 },
    {  21.5f, 19632 },
    {  22.0f, 19952 },
    {  22.5f, 20256 },
    {  23.0f, 20576 },
    {  23.5f, 20880 },
    {  24.0f, 21200 },
    {  24.5f, 21520 },
    {  25.0f, 21840 },
    {  25.5f, 22160 },
    {  26.0f, 22480 },
    {  26.5f, 22800 },
    {  27.0f, 23120 },
    {  27.5f, 23456 },
    {  28.0f, 23776 },
    {  28.5f, 24096 },
    {  29.0f, 24432 },
    {  29.5f, 24752 },
    {  30.0f, 25088 },
    {  30.5f, 25408 },
    {  31.0f, 25744 },
    {  31.5f, 26080 },
    {  32.0f, 26400 },
    {  32.5f, 26736 },
    {  33.0f, 27056 },
    {  33.5f, 27392 },
    {  34.0f, 27728 },
    {  34.5f, 28048 },
    {  35.0f, 28384 },
    {  35.5f, 28720 },
    {  36.0f, 29040 },
    {  36.5f, 29376 },
    {  37.0f, 29712 },
    {  37.5f, 30032 },
    {  38.0f, 30368 },
    {  38.5f, 30688 },
    {  39.0f, 31024 },
    {  39.5f, 31344 },
    {  40.0f, 31664 },
    {  40.5f, 32000 },
    {  41.0f, 32320 },
    {  41.5f, 32640 },
    {  42.0f, 32960 },
    {  42.5f, 33280 },
    {  43.0f, 33600 },
    {  43.5f, 33920 },
    {  44.0f, 34240 },
    {  44.5f, 34560 },
    {  45.0f, 34880 },
    {  45.5f, 35184 },
    {  46.0f, 35504 },
    {  46.5f, 35808 },
    {  47.0f, 36112 },
    {  47.5f, 36432 },
    {  48.0f, 36736 },
    {  48.5f, 37040 },
    {  49.0f, 37344 },
    {  49.5f, 37632 },
    {  50.0f, 37936 },
    {  50.5f, 38240 },
    {  51.0f, 38528 },
    {  51.5f, 38832 },
    {  52.0f, 39120 },
    {  52.5f, 39408 },
    {  53.0f, 39696 },
    {  53.5f, 39984 },
    {  54.0f, 40256 },
    {  54.5f, 40544 },
    {  55.0f, 40832 },
    {  55.5f, 41104 },
    {  56.0f, 41376 },
    {  56.5f, 41648 },
    {  57.0f, 41920 },
    {  57.5f, 42192 },
    {  58.0f, 42464 },
    {  58.5f, 42720 },
    {  59.0f, 42992 },
    {  59.5f, 43248 },
    {  60.0f, 43504 },
    {  60.5f, 43760 },
    {  61.0f, 44016 },
    {  61.5f, 44272 },
    {  62.0f, 44512 },
    {  62.5f, 44752 },
    {  63.0f, 45008 },
    {  63.5f, 45248 },
    {  64.0f, 45488 },
    {  64.5f, 45728 },
    {  65.0f, 45952 },
    {  65.5f, 46192 },
    {  66.0f, 46416 },
    {  66.5f, 46656 },
    {  67.0f, 46880 },
    {  67.5f, 47104 },
    {  68.0f, 47328 },
    {  68.5f, 47536 },
    {  69.0f, 47760 },
    {  69.5f, 47968 },
    {  70.0f, 48176 },
    {  70.5f, 48400 },
    {  71.0f, 48608 },
    {  71.5f, 48800 },
    {  72.0f, 49008 },
    {  72.5f, 49216 },
    {  73.0f, 49408 },
    {  73.5f, 49600 },
    {  74.0f, 49808 },
    {  74.5f, 50000 },
    {  75.0f, 50176 },
    {  75.5f, 50368 },
    {  76.0f, 50560 },
    {  76.5f, 50736 },
    {  77.0f, 50928 },
    {  77.5f, 51104 },
    {  78.0f, 51280 },
    {  78.5f, 51456 },
    {  79.0f, 51632 },
    {  79.5f, 51792 },
    {  80.0f, 51968 },
    {  80.5f, 52128 },
    {  81.0f, 52304 },
    {  81.5f, 52464 },
    {  82.0f, 52624 },
    {  82.5f, 52784 },
    {  83.0f, 52944 },
    {  83.5f, 53088 },
    {  84.0f, 53248 },
    {  84.5f, 53408 },
    {  85.0f, 53552 },
    {  85.5f, 53696 },
    {  86.0f, 53840 },
    {  86.5f, 53984 },
    {  87.0f, 54128 },
    {  87.5f, 54272 },
    {  88.0f, 54416 },
    {  88.5f, 54544 },
    {  89.0f, 54688 },
    {  89.5f, 54816 },
    {  90.0f, 54944 },
    {  90.5f, 55072 },
    {  91.0f, 55200 },
    {  91.5f, 55328 },
    {  92.0f, 55456 },
    {  92.5f, 55584 },
    {  93.0f, 55712 },
    {  93.5f, 55824 },
    {  94.0f, 55952 },
    {  94.5f, 56064 },
    {  95.0f, 56176 },
    {  95.5f, 56288 },
    {  96.0f, 56400 },
    {  96.5f, 56512 },
    {  97.0f, 56624 },
    {  97.5f, 56736 },
    {  98.0f, 56848 },
    {  98.5f, 56944 },
    {  99.0f, 57056 },
    {  99.5f, 57152 },
    { 100.0f, 57264 },
    { 100.5f, 57360 },
    { 101.0f, 57456 },
    { 101.5f, 57552 },
    { 102.0f, 57648 },
    { 102.5f, 57744 },
    { 103.0f, 57840 },
    { 103.5f, 57936 },
    { 104.0f, 58032 },
    { 104.5f, 58112 },
    { 105.0f, 58208 },
    { 105.5f, 58288 },
    { 106.0f, 58384 },
    { 106.5f, 58464 },
    { 107.0f, 58544 },
    { 107.5f, 58640 },
    { 108.0f, 58720 },
    { 108.5f, 58800 },
    { 109.0f, 58880 },
    { 109.5f, 58960 },
    { 110.0f, 59040 },
    { 110.5f, 59120 },
    { 111.0f, 59184 },
    { 111.5f, 59264 },
    { 112.0f, 59344 },
    { 112.5f, 59408 },
    { 113.0f, 59488 },
    { 113.5f, 59552 },
    { 114.0f, 59632 },
    { 114.5f, 59696 },
    { 115.0f, 59760 },
    { 115.5f, 59824 },
    { 116.0f, 59904 },
    { 116.5f, 59968 },
    { 117.0f, 60032 },
    { 117.5f, 60096 },
    { 118.0f, 60160 },
    { 118.5f, 60224 },
    { 119.0f, 60272 },
    { 119.5f, 60336 },
    { 120.0f, 60400 },
    { 120.5f, 60464 },
    { 121.0f, 60512 },
    { 121.5f, 60576 },
    { 122.0f, 60624 },
    { 122.5f, 60688 },
    { 123.0f, 60736 },
    { 123.5f, 60800 },
    { 124.0f, 60848 },
    { 124.5f, 60912 },
    { 125.0f, 60960 },
};

/* Function to calculate temperature using linear interpolation based on LUT */
float Get_Temperature_From_Table(uint16_t adc_raw_16bit)
{
    uint16_t adc_value = adc_raw_16bit;

    if (adc_value <= NTC_LUT[0].adc)
        return NTC_LUT[0].temp_c;

    if (adc_value >= NTC_LUT[NTC_TABLE_SIZE - 1].adc)
        return NTC_LUT[NTC_TABLE_SIZE - 1].temp_c;

    for (uint16_t i = 0; i < (NTC_TABLE_SIZE - 1U); i++)
    {
        uint16_t adc_lo = NTC_LUT[i].adc;
        uint16_t adc_hi = NTC_LUT[i + 1U].adc;

        if ((adc_value >= adc_lo) && (adc_value <= adc_hi))
        {
            float temp_lo = NTC_LUT[i].temp_c;
            float temp_hi = NTC_LUT[i + 1U].temp_c;

            if (adc_hi == adc_lo)
                return temp_lo;

            float ratio = ((float)adc_value - (float)adc_lo) /
                          ((float)adc_hi - (float)adc_lo);

            return temp_lo + (ratio * (temp_hi - temp_lo));
        }
    }

    return -999.0f;
}

float Get_Temperature_From_Table_Nearest(uint16_t adc_raw_16bit)
{
    uint16_t adc_value = adc_raw_16bit;

    if (adc_value <= NTC_LUT[0].adc)
        return NTC_LUT[0].temp_c;

    if (adc_value >= NTC_LUT[NTC_TABLE_SIZE - 1].adc)
        return NTC_LUT[NTC_TABLE_SIZE - 1].temp_c;

    for (uint16_t i = 0; i < (NTC_TABLE_SIZE - 1U); i++)
    {
        uint16_t adc_lo = NTC_LUT[i].adc;
        uint16_t adc_hi = NTC_LUT[i + 1U].adc;

        if ((adc_value >= adc_lo) && (adc_value <= adc_hi))
        {
            uint16_t diff_lo = adc_value - adc_lo;
            uint16_t diff_hi = adc_hi - adc_value;

            if (diff_lo <= diff_hi)
                return NTC_LUT[i].temp_c;
            else
                return NTC_LUT[i + 1U].temp_c;
        }
    }

    return -999.0f;
}

/* Function to get calibrated VBUS voltage in floating point */
float Get_Calibrated_VBUS_V(void)
{
    float raw_calculated_voltage;
    float final_calibrated_voltage;
    uint16_t raw_voltage_d;

    /* 1. Retrieve Raw ADC Data for VBUS */
    raw_voltage_d = VBS_GetAvBusVoltage_d((BusVoltageSensor_Handle_t *)&BusVoltageSensor_M1);

    /* 2. Calculate the initial floating-point voltage using ST's default conversion factor */
    raw_calculated_voltage = (float)raw_voltage_d * ((BusVoltageSensor_Handle_t *)&BusVoltageSensor_M1)->ConversionFactor / 65536.0f;

    /* 3. Apply secondary linear calibration formula: y = mx + c */
    final_calibrated_voltage = (raw_calculated_voltage * VBUS_CALIB_GAIN) + VBUS_CALIB_OFFSET;

    /* 4. Apply Deadband: Mask out USB backfeed voltage and negative noise */
    if (final_calibrated_voltage < VBUS_NOISE_DEADBAND_V)
    {
        final_calibrated_voltage = 0.0f;
    }

    return final_calibrated_voltage;
}

static inline void UVW_TestPins_SetLow(void)
{
  HAL_GPIO_WritePin(U_TEST_PORT, U_TEST_PIN, GPIO_PIN_RESET);
  HAL_GPIO_WritePin(V_TEST_PORT, V_TEST_PIN, GPIO_PIN_RESET);
  HAL_GPIO_WritePin(W_TEST_PORT, W_TEST_PIN, GPIO_PIN_RESET);
}

void TIM1_UVW_SelfTest_Task_SDK(void)
{
    static uint32_t s_last_toggle = 0u;
    uint32_t now = HAL_GetTick();

    /* Get the motor state machine status via SDK */
    MCI_State_t mcState = MC_GetSTMStateMotor1();

    /* Check PWM pulse width only when in starting or running state */
    if (mcState == START || mcState == RUN)
    {
        if ((now - s_last_toggle) >= UVW_TOGGLE_MS)
        {
            /* Read-only access to TIM1 Compare registers, without interfering with FOC */
            bool pwm_u_active = (TIM1->CCR1 > 0);
            bool pwm_v_active = (TIM1->CCR2 > 0);
            bool pwm_w_active = (TIM1->CCR3 > 0);

            if (pwm_u_active) HAL_GPIO_TogglePin(U_TEST_PORT, U_TEST_PIN);
            else HAL_GPIO_WritePin(U_TEST_PORT, U_TEST_PIN, GPIO_PIN_RESET);

            if (pwm_v_active) HAL_GPIO_TogglePin(V_TEST_PORT, V_TEST_PIN);
            else HAL_GPIO_WritePin(V_TEST_PORT, V_TEST_PIN, GPIO_PIN_RESET);

            if (pwm_w_active) HAL_GPIO_TogglePin(W_TEST_PORT, W_TEST_PIN);
            else HAL_GPIO_WritePin(W_TEST_PORT, W_TEST_PIN, GPIO_PIN_RESET);

            s_last_toggle = now;
        }
    }
    else
    {
        UVW_TestPins_SetLow();
    }
}

void Vdc_check_fun_SDK(void)
{
    static uint32_t s_last_vdc_tick = 0u;
    static uint32_t s_vdc_period_ms = 10u;
    static bool s_is_vdc_ok = false; /* Hysteresis state flag */
    uint32_t now = HAL_GetTick();

    if ((now - s_last_vdc_tick) < s_vdc_period_ms) return;
    s_last_vdc_tick = now;

    /* Get the filtered bus voltage in Volts */
    float real_voltage_V = Get_Calibrated_VBUS_V();

    /* Hysteresis parameters for VBUS (Target: 2V ~ 50V) */
    const uint16_t VDC_LOW_FAIL       = 2;
    const uint16_t VDC_LOW_RECOVER    = 3;  /* Require 3V to recover from low voltage */
    const uint16_t VDC_HIGH_FAIL      = 50;
    const uint16_t VDC_HIGH_RECOVER   = 48; /* Require 48V to recover from over voltage */

    /* Hysteresis logic evaluation */
    if (!s_is_vdc_ok)
    {
        /* Turn ON condition: Voltage must be safely inside the inner window */
        if ((real_voltage_V >= VDC_LOW_RECOVER) && (real_voltage_V <= VDC_HIGH_RECOVER))
        {
            s_is_vdc_ok = true;
        }
    }
    else
    {
        /* Turn OFF condition: Voltage hits the absolute outer limits */
        if ((real_voltage_V < VDC_LOW_FAIL) || (real_voltage_V > VDC_HIGH_FAIL))
        {
            s_is_vdc_ok = false;
        }
    }

    /* Output evaluation based on state flag */
    if (s_is_vdc_ok)
    {
        HAL_GPIO_TogglePin(GPIOB, GPIO_PIN_8);
        s_vdc_period_ms = 100u;   /* Normal state */
    }
    else
    {
        HAL_GPIO_WritePin(GPIOB, GPIO_PIN_8, GPIO_PIN_SET);
        s_vdc_period_ms = 100u;  /* Abnormal state */
    }
}

void TSNS_Check_SDK(void)
{
    static uint32_t s_last_tsns_tick = 0;
    static bool s_is_tsns_ok = false; /* Hysteresis state flag */
    uint32_t now = HAL_GetTick();

    if ((now - s_last_tsns_tick) < 100u) return;
    s_last_tsns_tick = now;

    /* Get the raw 16-bit ADC value from SDK */
	uint16_t raw_temp_d = NTC_GetAvTemp_d(&TempSensor_M1);

    /* Pure lookup table only, no linear interpolation */
    float table_temp_C = Get_Temperature_From_Table_Nearest(raw_temp_d);

    /* Hysteresis parameters for TSNS (Target: -10 C ~ 120 C) */
    const int16_t TSNS_LOW_FAIL     = -10;
    const int16_t TSNS_LOW_RECOVER  = -5;  /* Require -5 C to recover from cold */
    const int16_t TSNS_HIGH_FAIL    = 120;
    const int16_t TSNS_HIGH_RECOVER = 110; /* Require 110 C to recover from overheat */

    /* Hysteresis logic evaluation */
    if (!s_is_tsns_ok)
    {
        /* Turn ON condition: Temperature must be safely inside the inner window */
        if ((table_temp_C >= TSNS_LOW_RECOVER) && (table_temp_C <= TSNS_HIGH_RECOVER))
        {
            s_is_tsns_ok = true;
        }
    }
    else
    {
        /* Turn OFF condition: Temperature hits the absolute outer limits */
        if ((table_temp_C <= TSNS_LOW_FAIL) || (table_temp_C >= TSNS_HIGH_FAIL))
        {
            s_is_tsns_ok = false;
        }
    }

    if (s_is_tsns_ok)
    {
        HAL_GPIO_TogglePin(GPIOB, GPIO_PIN_9);
    }
    else
    {
        HAL_GPIO_WritePin(GPIOB, GPIO_PIN_9, GPIO_PIN_RESET);
    }
}

void Isns_Check_SDK(void)
{
    static uint32_t s_isns_last_toggle = 0u;
    static bool s_is_isns_u_ok = false; /* Hysteresis state for Phase U */
    static bool s_is_isns_v_ok = false; /* Hysteresis state for Phase V */

    /* If the motor has already started, stop testing the pins */
    MCI_State_t mcState = MC_GetSTMStateMotor1();
    if (mcState == START || mcState == RUN)
    {
        HAL_GPIO_WritePin(ISNS_U_CHECK_PORT, ISNS_U_CHECK_PIN, GPIO_PIN_RESET);
        HAL_GPIO_WritePin(ISNS_V_CHECK_PORT, ISNS_V_CHECK_PIN, GPIO_PIN_RESET);
        return;
    }

    if ((HAL_GetTick() - s_isns_last_toggle) >= ISNS_CHECK_TOGGLE_MS)
    {
        PWMC_ICS_Handle_t *pIcsHandle = (PWMC_ICS_Handle_t *)pwmcHandle[0];

        /* Read the converted digital value (0~4095) */
        uint16_t raw_adc_A = (pIcsHandle->pParams_str->ADCx_1->JDR1) >> 4;
        uint16_t raw_adc_B = (pIcsHandle->pParams_str->ADCx_2->JDR1) >> 4;

        /* Hysteresis bounds for ISNS (Target: 1985 ~ 2110) */
        const uint16_t ISNS_LOWER_FAIL    = 1985;
        const uint16_t ISNS_LOWER_RECOVER = 2005; /* +20 margin to recover */
        const uint16_t ISNS_UPPER_FAIL    = 2110;
        const uint16_t ISNS_UPPER_RECOVER = 2090; /* -20 margin to recover */

        /* Validate hardware Isns Phase A with Hysteresis */
        if (!s_is_isns_u_ok)
        {
            if ((raw_adc_A >= ISNS_LOWER_RECOVER) && (raw_adc_A <= ISNS_UPPER_RECOVER)) s_is_isns_u_ok = true;
        }
        else
        {
            if ((raw_adc_A < ISNS_LOWER_FAIL) || (raw_adc_A > ISNS_UPPER_FAIL)) s_is_isns_u_ok = false;
        }

        if (s_is_isns_u_ok) HAL_GPIO_TogglePin(ISNS_U_CHECK_PORT, ISNS_U_CHECK_PIN);
        else HAL_GPIO_WritePin(ISNS_U_CHECK_PORT, ISNS_U_CHECK_PIN, GPIO_PIN_RESET);

        /* Validate hardware Isns Phase B with Hysteresis */
        if (!s_is_isns_v_ok)
        {
            if ((raw_adc_B >= ISNS_LOWER_RECOVER) && (raw_adc_B <= ISNS_UPPER_RECOVER)) s_is_isns_v_ok = true;
        }
        else
        {
            if ((raw_adc_B < ISNS_LOWER_FAIL) || (raw_adc_B > ISNS_UPPER_FAIL)) s_is_isns_v_ok = false;
        }

        if (s_is_isns_v_ok) HAL_GPIO_TogglePin(ISNS_V_CHECK_PORT, ISNS_V_CHECK_PIN);
        else HAL_GPIO_WritePin(ISNS_V_CHECK_PORT, ISNS_V_CHECK_PIN, GPIO_PIN_RESET);

        s_isns_last_toggle = HAL_GetTick();
    }
}

void GaN_Safe_AutoStart_Task(void)
{
    static uint32_t s_stable_voltage_start_time = 0;
    static bool s_is_voltage_stable = false;

    /* This flag allows clearing severe faults after a manual power cycle */
    static bool s_allow_reset_after_power_cycle = false;

    MCI_State_t mcState = MC_GetSTMStateMotor1();
    float real_voltage_V = Get_Calibrated_VBUS_V();

    /* 1. Reset Detection: Detect if 12V was removed */
    if (real_voltage_V < 4)
    {
        s_is_voltage_stable = false;
        s_allow_reset_after_power_cycle = true;
    }

    /* 2. Safe fault reset logic (to protect GaN devices) */
    if (mcState == FAULT_OVER)
    {
        uint16_t pastFaults = MC_GetOccurredFaultsMotor1();

        /* Clear fault IF it was Under-Voltage OR the user performed a power cycle */
        if (pastFaults == MC_UNDER_VOLT || s_allow_reset_after_power_cycle)
        {
            MC_AcknowledgeFaultMotor1();
            s_allow_reset_after_power_cycle = false;
        }
        else
        {
            HAL_GPIO_WritePin(ISNS_V_CHECK_PORT, ISNS_V_CHECK_PIN, GPIO_PIN_SET);
            HAL_GPIO_WritePin(ISNS_U_CHECK_PORT, ISNS_U_CHECK_PIN, GPIO_PIN_SET);
        }
    }
    /* 3. Stabilization delay and safe start logic */
    else if (mcState == IDLE)
    {
        if (real_voltage_V >= 4 && real_voltage_V <= 50)
        {
            if (!s_is_voltage_stable)
            {
                s_stable_voltage_start_time = HAL_GetTick();
                s_is_voltage_stable = true;
            }
            else
            {
                if ((HAL_GetTick() - s_stable_voltage_start_time) > 500u)
                {
                    MC_StartMotor1();
                }
            }
        }
        else
        {
            s_is_voltage_stable = false;
        }
    }
    else
    {
        s_is_voltage_stable = false;
    }
}

// UART transmission setting
void UART3_Print(const char *msg)
{
    HAL_UART_Transmit(&huart3, (uint8_t *)msg, strlen(msg), 100);
}

void Debug_Print_Task(void)
{
    static uint32_t s_last_print = 0;
    uint32_t now = HAL_GetTick();

    // Print every 500ms to avoid flooding the UART port
    if ((now - s_last_print) < 500u)
        return;
    s_last_print = now;

    char msg[250];
    MCI_State_t mcState = MC_GetSTMStateMotor1();

    /* Retrieve Voltage Data (Physical + Raw ADC) */
    uint16_t raw_voltage_d  = VBS_GetAvBusVoltage_d((BusVoltageSensor_Handle_t *)&BusVoltageSensor_M1);
    /* Calculate true floating-point voltage using the raw value and conversion factor */
	/* Ensure the division is done using a floating-point number (65536.0) */
    float real_voltage_V = Get_Calibrated_VBUS_V();
    /* Temperature: pure lookup table only */
    uint16_t raw_temp_d = NTC_GetAvTemp_d(&TempSensor_M1);
    float table_temp_C = Get_Temperature_From_Table_Nearest(raw_temp_d);

    /* Retrieve Current Data (Raw ADC) */
    PWMC_ICS_Handle_t *pIcsHandle = (PWMC_ICS_Handle_t *)pwmcHandle[0];
    uint16_t raw_adc_A = (pIcsHandle->pParams_str->ADCx_1->JDR1) >> 4;
    uint16_t raw_adc_B = (pIcsHandle->pParams_str->ADCx_2->JDR1) >> 4;

    // Get PWM enable status
	uint8_t pwm_is_on = (TIM1->BDTR & TIM_BDTR_MOE) ? 1 : 0;

    // Format the status message including RAW data for TSNS and VBUS
    snprintf(msg, sizeof(msg),
             "ST=%d, VBUS=%.2fV(RAW:%u), TSNS=%.1fC(RAW:%u), I_U=%u, I_V=%u, PWM=%d\r\n",
             mcState, real_voltage_V, raw_voltage_d, table_temp_C, raw_temp_d, raw_adc_A, raw_adc_B, pwm_is_on);

    UART3_Print(msg);
}
/* USER CODE END 0 */

int main(void)
{

  /* MCU Configuration--------------------------------------------------------*/

  /* Reset of all peripherals, Initializes the Flash interface and the Systick. */
  HAL_Init();

  /* Configure the system clock */
  SystemClock_Config();

  /* Initialize all configured peripherals */
  MX_GPIO_Init();
  MX_DMA_Init();
  MX_ADC1_Init();
  MX_ADC2_Init();
  MX_CORDIC_Init();
  MX_TIM1_Init();
  MX_USART3_UART_Init();
  MX_MotorControl_Init();

  /* Initialize interrupts */
  MX_NVIC_Init();

  /* Infinite loop */
  /* USER CODE BEGIN WHILE */
  while (1)
  {
	 TIM1_UVW_SelfTest_Task_SDK();
	 Vdc_check_fun_SDK();
	 Isns_Check_SDK();
	 TSNS_Check_SDK();
	 // Execute the safe auto-start and protection logic for GaN
	 GaN_Safe_AutoStart_Task();
	 Debug_Print_Task();
    /* USER CODE END WHILE */

  }
}

void SystemClock_Config(void)
{
  RCC_OscInitTypeDef RCC_OscInitStruct = {0};
  RCC_ClkInitTypeDef RCC_ClkInitStruct = {0};

  /** Configure the main internal regulator output voltage
  */
  HAL_PWREx_ControlVoltageScaling(PWR_REGULATOR_VOLTAGE_SCALE1_BOOST);

  /** Initializes the RCC Oscillators according to the specified parameters
  * in the RCC_OscInitTypeDef structure.
  */
  RCC_OscInitStruct.OscillatorType = RCC_OSCILLATORTYPE_HSI;
  RCC_OscInitStruct.HSIState = RCC_HSI_ON;
  RCC_OscInitStruct.HSICalibrationValue = RCC_HSICALIBRATION_DEFAULT;
  RCC_OscInitStruct.PLL.PLLState = RCC_PLL_ON;
  RCC_OscInitStruct.PLL.PLLSource = RCC_PLLSOURCE_HSI;
  RCC_OscInitStruct.PLL.PLLM = RCC_PLLM_DIV4;
  RCC_OscInitStruct.PLL.PLLN = 85;
  RCC_OscInitStruct.PLL.PLLP = RCC_PLLP_DIV8;
  RCC_OscInitStruct.PLL.PLLQ = RCC_PLLQ_DIV2;
  RCC_OscInitStruct.PLL.PLLR = RCC_PLLR_DIV2;
  if (HAL_RCC_OscConfig(&RCC_OscInitStruct) != HAL_OK)
  {
    Error_Handler();
  }

  /** Initializes the CPU, AHB and APB buses clocks
  */
  RCC_ClkInitStruct.ClockType = RCC_CLOCKTYPE_HCLK|RCC_CLOCKTYPE_SYSCLK
                              |RCC_CLOCKTYPE_PCLK1|RCC_CLOCKTYPE_PCLK2;
  RCC_ClkInitStruct.SYSCLKSource = RCC_SYSCLKSOURCE_PLLCLK;
  RCC_ClkInitStruct.AHBCLKDivider = RCC_SYSCLK_DIV1;
  RCC_ClkInitStruct.APB1CLKDivider = RCC_HCLK_DIV1;
  RCC_ClkInitStruct.APB2CLKDivider = RCC_HCLK_DIV1;

  if (HAL_RCC_ClockConfig(&RCC_ClkInitStruct, FLASH_LATENCY_4) != HAL_OK)
  {
    Error_Handler();
  }
}

/**
  * @brief NVIC Configuration.
  * @retval None
  */
static void MX_NVIC_Init(void)
{
  /* USART3_IRQn interrupt configuration */
  HAL_NVIC_SetPriority(USART3_IRQn, 3, 1);
  HAL_NVIC_EnableIRQ(USART3_IRQn);
  /* DMA1_Channel1_IRQn interrupt configuration */
  HAL_NVIC_SetPriority(DMA1_Channel1_IRQn, 3, 0);
  HAL_NVIC_EnableIRQ(DMA1_Channel1_IRQn);
  /* TIM1_BRK_TIM15_IRQn interrupt configuration */
  HAL_NVIC_SetPriority(TIM1_BRK_TIM15_IRQn, 4, 1);
  HAL_NVIC_EnableIRQ(TIM1_BRK_TIM15_IRQn);
  /* TIM1_UP_TIM16_IRQn interrupt configuration */
  HAL_NVIC_SetPriority(TIM1_UP_TIM16_IRQn, 0, 0);
  HAL_NVIC_EnableIRQ(TIM1_UP_TIM16_IRQn);
  /* ADC1_2_IRQn interrupt configuration */
  HAL_NVIC_SetPriority(ADC1_2_IRQn, 2, 0);
  HAL_NVIC_EnableIRQ(ADC1_2_IRQn);
}

static void MX_ADC1_Init(void)
{

  ADC_MultiModeTypeDef multimode = {0};
  ADC_InjectionConfTypeDef sConfigInjected = {0};
  ADC_ChannelConfTypeDef sConfig = {0};

  /** Common config
  */
  hadc1.Instance = ADC1;
  hadc1.Init.ClockPrescaler = ADC_CLOCK_ASYNC_DIV1;
  hadc1.Init.Resolution = ADC_RESOLUTION_12B;
  hadc1.Init.DataAlign = ADC_DATAALIGN_LEFT;
  hadc1.Init.GainCompensation = 0;
  hadc1.Init.ScanConvMode = ADC_SCAN_DISABLE;
  hadc1.Init.EOCSelection = ADC_EOC_SINGLE_CONV;
  hadc1.Init.LowPowerAutoWait = DISABLE;
  hadc1.Init.ContinuousConvMode = DISABLE;
  hadc1.Init.NbrOfConversion = 1;
  hadc1.Init.DiscontinuousConvMode = DISABLE;
  hadc1.Init.ExternalTrigConv = ADC_SOFTWARE_START;
  hadc1.Init.ExternalTrigConvEdge = ADC_EXTERNALTRIGCONVEDGE_NONE;
  hadc1.Init.DMAContinuousRequests = DISABLE;
  hadc1.Init.Overrun = ADC_OVR_DATA_PRESERVED;
  hadc1.Init.OversamplingMode = DISABLE;
  if (HAL_ADC_Init(&hadc1) != HAL_OK)
  {
    Error_Handler();
  }

  /** Configure the ADC multi-mode
  */
  multimode.Mode = ADC_MODE_INDEPENDENT;
  if (HAL_ADCEx_MultiModeConfigChannel(&hadc1, &multimode) != HAL_OK)
  {
    Error_Handler();
  }

  /** Configure Injected Channel
  */
  sConfigInjected.InjectedChannel = ADC_CHANNEL_2;
  sConfigInjected.InjectedRank = ADC_INJECTED_RANK_1;
  sConfigInjected.InjectedSamplingTime = ADC_SAMPLETIME_6CYCLES_5;
  sConfigInjected.InjectedSingleDiff = ADC_SINGLE_ENDED;
  sConfigInjected.InjectedOffsetNumber = ADC_OFFSET_NONE;
  sConfigInjected.InjectedOffset = 0;
  sConfigInjected.InjectedNbrOfConversion = 1;
  sConfigInjected.InjectedDiscontinuousConvMode = DISABLE;
  sConfigInjected.AutoInjectedConv = DISABLE;
  sConfigInjected.QueueInjectedContext = DISABLE;
  sConfigInjected.ExternalTrigInjecConv = ADC_EXTERNALTRIGINJEC_T1_TRGO;
  sConfigInjected.ExternalTrigInjecConvEdge = ADC_EXTERNALTRIGINJECCONV_EDGE_RISING;
  sConfigInjected.InjecOversamplingMode = DISABLE;
  if (HAL_ADCEx_InjectedConfigChannel(&hadc1, &sConfigInjected) != HAL_OK)
  {
    Error_Handler();
  }

  /** Configure Regular Channel
  */
  sConfig.Channel = ADC_CHANNEL_10;
  sConfig.Rank = ADC_REGULAR_RANK_1;
  sConfig.SamplingTime = ADC_SAMPLETIME_47CYCLES_5;
  sConfig.SingleDiff = ADC_SINGLE_ENDED;
  sConfig.OffsetNumber = ADC_OFFSET_NONE;
  sConfig.Offset = 0;
  if (HAL_ADC_ConfigChannel(&hadc1, &sConfig) != HAL_OK)
  {
    Error_Handler();
  }
  /* USER CODE BEGIN ADC1_Init 2 */
  /* Run hardware calibration for ADC1 before starting the motor control SDK */
  if (HAL_ADCEx_Calibration_Start(&hadc1, ADC_SINGLE_ENDED) != HAL_OK)
  {
    Error_Handler();
  }
  /* USER CODE END ADC1_Init 2 */

}

static void MX_ADC2_Init(void)
{

  ADC_InjectionConfTypeDef sConfigInjected = {0};
  ADC_ChannelConfTypeDef sConfig = {0};

  /** Common config
  */
  hadc2.Instance = ADC2;
  hadc2.Init.ClockPrescaler = ADC_CLOCK_ASYNC_DIV1;
  hadc2.Init.Resolution = ADC_RESOLUTION_12B;
  hadc2.Init.DataAlign = ADC_DATAALIGN_LEFT;
  hadc2.Init.GainCompensation = 0;
  hadc2.Init.ScanConvMode = ADC_SCAN_DISABLE;
  hadc2.Init.EOCSelection = ADC_EOC_SINGLE_CONV;
  hadc2.Init.LowPowerAutoWait = DISABLE;
  hadc2.Init.ContinuousConvMode = DISABLE;
  hadc2.Init.NbrOfConversion = 1;
  hadc2.Init.DiscontinuousConvMode = DISABLE;
  hadc2.Init.ExternalTrigConv = ADC_SOFTWARE_START;
  hadc2.Init.ExternalTrigConvEdge = ADC_EXTERNALTRIGCONVEDGE_NONE;
  hadc2.Init.DMAContinuousRequests = DISABLE;
  hadc2.Init.Overrun = ADC_OVR_DATA_PRESERVED;
  hadc2.Init.OversamplingMode = DISABLE;
  if (HAL_ADC_Init(&hadc2) != HAL_OK)
  {
    Error_Handler();
  }

  /** Configure Injected Channel
  */
  sConfigInjected.InjectedChannel = ADC_CHANNEL_13;
  sConfigInjected.InjectedRank = ADC_INJECTED_RANK_1;
  sConfigInjected.InjectedSamplingTime = ADC_SAMPLETIME_6CYCLES_5;
  sConfigInjected.InjectedSingleDiff = ADC_SINGLE_ENDED;
  sConfigInjected.InjectedOffsetNumber = ADC_OFFSET_NONE;
  sConfigInjected.InjectedOffset = 0;
  sConfigInjected.InjectedNbrOfConversion = 1;
  sConfigInjected.InjectedDiscontinuousConvMode = DISABLE;
  sConfigInjected.AutoInjectedConv = DISABLE;
  sConfigInjected.QueueInjectedContext = DISABLE;
  sConfigInjected.ExternalTrigInjecConv = ADC_EXTERNALTRIGINJEC_T1_TRGO;
  sConfigInjected.ExternalTrigInjecConvEdge = ADC_EXTERNALTRIGINJECCONV_EDGE_RISING;
  sConfigInjected.InjecOversamplingMode = DISABLE;
  if (HAL_ADCEx_InjectedConfigChannel(&hadc2, &sConfigInjected) != HAL_OK)
  {
    Error_Handler();
  }

  /** Configure Regular Channel
  */
  sConfig.Channel = ADC_CHANNEL_3;
  sConfig.Rank = ADC_REGULAR_RANK_1;
  sConfig.SamplingTime = ADC_SAMPLETIME_47CYCLES_5;
  sConfig.SingleDiff = ADC_SINGLE_ENDED;
  sConfig.OffsetNumber = ADC_OFFSET_NONE;
  sConfig.Offset = 0;
  if (HAL_ADC_ConfigChannel(&hadc2, &sConfig) != HAL_OK)
  {
    Error_Handler();
  }
  /* USER CODE BEGIN ADC2_Init 2 */
  /* Run hardware calibration for ADC2 before starting the motor control SDK */
  if (HAL_ADCEx_Calibration_Start(&hadc2, ADC_SINGLE_ENDED) != HAL_OK)
  {
    Error_Handler();
  }
  /* USER CODE END ADC2_Init 2 */

}

static void MX_CORDIC_Init(void)
{

  hcordic.Instance = CORDIC;
  if (HAL_CORDIC_Init(&hcordic) != HAL_OK)
  {
    Error_Handler();
  }

}

static void MX_TIM1_Init(void)
{

  TIM_MasterConfigTypeDef sMasterConfig = {0};
  TIMEx_BreakInputConfigTypeDef sBreakInputConfig = {0};
  TIM_OC_InitTypeDef sConfigOC = {0};
  TIM_BreakDeadTimeConfigTypeDef sBreakDeadTimeConfig = {0};

  htim1.Instance = TIM1;
  htim1.Init.Prescaler = ((TIM_CLOCK_DIVIDER) - 1);
  htim1.Init.CounterMode = TIM_COUNTERMODE_CENTERALIGNED1;
  htim1.Init.Period = ((PWM_PERIOD_CYCLES) / 2);
  htim1.Init.ClockDivision = TIM_CLOCKDIVISION_DIV2;
  htim1.Init.RepetitionCounter = (REP_COUNTER);
  htim1.Init.AutoReloadPreload = TIM_AUTORELOAD_PRELOAD_DISABLE;
  if (HAL_TIM_PWM_Init(&htim1) != HAL_OK)
  {
    Error_Handler();
  }
  sMasterConfig.MasterOutputTrigger = TIM_TRGO_OC4REF;
  sMasterConfig.MasterOutputTrigger2 = TIM_TRGO2_RESET;
  sMasterConfig.MasterSlaveMode = TIM_MASTERSLAVEMODE_DISABLE;
  if (HAL_TIMEx_MasterConfigSynchronization(&htim1, &sMasterConfig) != HAL_OK)
  {
    Error_Handler();
  }
  sBreakInputConfig.Source = TIM_BREAKINPUTSOURCE_BKIN;
  sBreakInputConfig.Enable = TIM_BREAKINPUTSOURCE_ENABLE;
  sBreakInputConfig.Polarity = TIM_BREAKINPUTSOURCE_POLARITY_LOW;
  if (HAL_TIMEx_ConfigBreakInput(&htim1, TIM_BREAKINPUT_BRK2, &sBreakInputConfig) != HAL_OK)
  {
    Error_Handler();
  }
  sConfigOC.OCMode = TIM_OCMODE_PWM1;
  sConfigOC.Pulse = ((PWM_PERIOD_CYCLES) / 4);
  sConfigOC.OCPolarity = TIM_OCPOLARITY_HIGH;
  sConfigOC.OCNPolarity = TIM_OCNPOLARITY_HIGH;
  sConfigOC.OCFastMode = TIM_OCFAST_DISABLE;
  sConfigOC.OCIdleState = TIM_OCIDLESTATE_RESET;
  sConfigOC.OCNIdleState = TIM_OCNIDLESTATE_RESET;
  if (HAL_TIM_PWM_ConfigChannel(&htim1, &sConfigOC, TIM_CHANNEL_1) != HAL_OK)
  {
    Error_Handler();
  }
  if (HAL_TIM_PWM_ConfigChannel(&htim1, &sConfigOC, TIM_CHANNEL_2) != HAL_OK)
  {
    Error_Handler();
  }
  if (HAL_TIM_PWM_ConfigChannel(&htim1, &sConfigOC, TIM_CHANNEL_3) != HAL_OK)
  {
    Error_Handler();
  }
  sConfigOC.OCMode = TIM_OCMODE_PWM2;
  sConfigOC.Pulse = (((PWM_PERIOD_CYCLES) / 2) - (HTMIN));
  if (HAL_TIM_PWM_ConfigChannel(&htim1, &sConfigOC, TIM_CHANNEL_4) != HAL_OK)
  {
    Error_Handler();
  }
  sBreakDeadTimeConfig.OffStateRunMode = TIM_OSSR_ENABLE;
  sBreakDeadTimeConfig.OffStateIDLEMode = TIM_OSSI_ENABLE;
  sBreakDeadTimeConfig.LockLevel = TIM_LOCKLEVEL_OFF;
  sBreakDeadTimeConfig.DeadTime = ((DEAD_TIME_COUNTS) / 2);
  sBreakDeadTimeConfig.BreakState = TIM_BREAK_DISABLE;
  sBreakDeadTimeConfig.BreakPolarity = TIM_BREAKPOLARITY_HIGH;
  sBreakDeadTimeConfig.BreakFilter = 0;
  sBreakDeadTimeConfig.BreakAFMode = TIM_BREAK_AFMODE_INPUT;
  sBreakDeadTimeConfig.Break2State = TIM_BREAK2_ENABLE;
  sBreakDeadTimeConfig.Break2Polarity = TIM_BREAK2POLARITY_HIGH;
  sBreakDeadTimeConfig.Break2Filter = 1;
  sBreakDeadTimeConfig.Break2AFMode = TIM_BREAK_AFMODE_INPUT;
  sBreakDeadTimeConfig.AutomaticOutput = TIM_AUTOMATICOUTPUT_DISABLE;
  if (HAL_TIMEx_ConfigBreakDeadTime(&htim1, &sBreakDeadTimeConfig) != HAL_OK)
  {
    Error_Handler();
  }
  HAL_TIM_MspPostInit(&htim1);

}

static void MX_USART3_UART_Init(void)
{

  huart3.Instance = USART3;
  huart3.Init.BaudRate = 115200;
  huart3.Init.WordLength = UART_WORDLENGTH_8B;
  huart3.Init.StopBits = UART_STOPBITS_1;
  huart3.Init.Parity = UART_PARITY_NONE;
  huart3.Init.Mode = UART_MODE_TX_RX;
  huart3.Init.HwFlowCtl = UART_HWCONTROL_NONE;
  huart3.Init.OverSampling = UART_OVERSAMPLING_16;
  huart3.Init.OneBitSampling = UART_ONE_BIT_SAMPLE_DISABLE;
  huart3.Init.ClockPrescaler = UART_PRESCALER_DIV1;
  huart3.AdvancedInit.AdvFeatureInit = UART_ADVFEATURE_NO_INIT;
  if (HAL_UART_Init(&huart3) != HAL_OK)
  {
    Error_Handler();
  }
  if (HAL_UARTEx_SetTxFifoThreshold(&huart3, UART_TXFIFO_THRESHOLD_1_8) != HAL_OK)
  {
    Error_Handler();
  }
  if (HAL_UARTEx_SetRxFifoThreshold(&huart3, UART_RXFIFO_THRESHOLD_1_8) != HAL_OK)
  {
    Error_Handler();
  }
  if (HAL_UARTEx_DisableFifoMode(&huart3) != HAL_OK)
  {
    Error_Handler();
  }

}

static void MX_DMA_Init(void)
{

  /* DMA controller clock enable */
  __HAL_RCC_DMAMUX1_CLK_ENABLE();
  __HAL_RCC_DMA1_CLK_ENABLE();

}

static void MX_GPIO_Init(void)
{
  GPIO_InitTypeDef GPIO_InitStruct = {0};

  /* GPIO Ports Clock Enable */
  __HAL_RCC_GPIOC_CLK_ENABLE();
  __HAL_RCC_GPIOF_CLK_ENABLE();
  __HAL_RCC_GPIOA_CLK_ENABLE();
  __HAL_RCC_GPIOB_CLK_ENABLE();

  /*Configure GPIO pin Output Level */
  HAL_GPIO_WritePin(GPIOB, ISNS_V_CHECK_Pin|ISNS_U_CHECK_Pin|U_TEST_PIN_Pin|V_TEST_PIN_Pin
                          |W_TEST_PIN_Pin|Vdc_check_Pin|Tsns_check_Pin, GPIO_PIN_RESET);

  /*Configure GPIO pins : ISNS_V_CHECK_Pin ISNS_U_CHECK_Pin U_TEST_PIN_Pin V_TEST_PIN_Pin
                           W_TEST_PIN_Pin Vdc_check_Pin Tsns_check_Pin */
  GPIO_InitStruct.Pin = ISNS_V_CHECK_Pin|ISNS_U_CHECK_Pin|U_TEST_PIN_Pin|V_TEST_PIN_Pin
                          |W_TEST_PIN_Pin|Vdc_check_Pin|Tsns_check_Pin;
  GPIO_InitStruct.Mode = GPIO_MODE_OUTPUT_PP;
  GPIO_InitStruct.Pull = GPIO_NOPULL;
  GPIO_InitStruct.Speed = GPIO_SPEED_FREQ_LOW;
  HAL_GPIO_Init(GPIOB, &GPIO_InitStruct);

}

void Error_Handler(void)
{
  __disable_irq();
  while (1)
  {
  }
}
